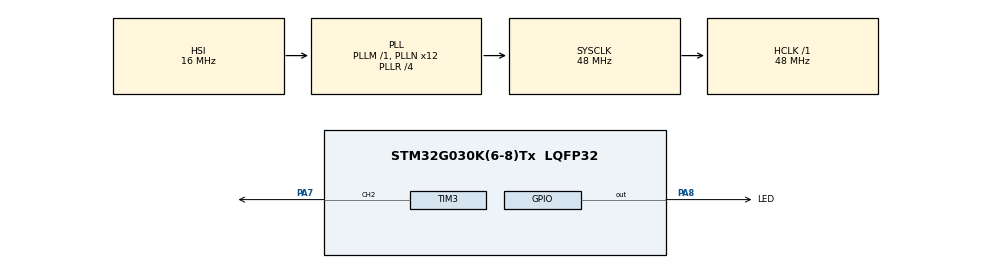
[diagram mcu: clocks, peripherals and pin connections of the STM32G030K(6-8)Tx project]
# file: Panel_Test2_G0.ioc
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Dma.Request0=TIM3_CH2
Dma.TIM3_CH2.0.Direction=DMA_MEMORY_TO_PERIPH
Dma.TIM3_CH2.0.EventEnable=DISABLE
Dma.TIM3_CH2.0.Instance=DMA1_Channel1
Dma.TIM3_CH2.0.MemDataAlignment=DMA_MDATAALIGN_BYTE
Dma.TIM3_CH2.0.MemInc=DMA_MINC_ENABLE
Dma.TIM3_CH2.0.Mode=DMA_CIRCULAR
Dma.TIM3_CH2.0.PeriphDataAlignment=DMA_PDATAALIGN_WORD
Dma.TIM3_CH2.0.PeriphInc=DMA_PINC_DISABLE
Dma.TIM3_CH2.0.Polarity=HAL_DMAMUX_REQ_GEN_RISING
Dma.TIM3_CH2.0.Priority=DMA_PRIORITY_VERY_HIGH
Dma.TIM3_CH2.0.RequestNumber=1
Dma.TIM3_CH2.0.SignalID=NONE
Dma.TIM3_CH2.0.SyncEnable=DISABLE
Dma.TIM3_CH2.0.SyncPolarity=HAL_DMAMUX_SYNC_NO_EVENT
Dma.TIM3_CH2.0.SyncRequestNumber=1
Dma.TIM3_CH2.0.SyncSignalID=NONE
Mcu.Family=STM32G0
Mcu.Name=STM32G030K(6-8)Tx
Mcu.Package=LQFP32
NVIC.DMA1_Channel1_IRQn=true\:0\:0\:false\:false\:true\:false\:true\:true
PA13.Mode=Serial_Wire
PA13.Signal=SYS_SWDIO
PA14-BOOT0.Mode=Serial_Wire
PA14-BOOT0.Signal=SYS_SWCLK
PA7.Signal=S_TIM3_CH2
PA8.GPIO_Label=LED
PA8.Signal=GPIO_Output
ProjectManager.HeapSize=0x200
ProjectManager.StackSize=0x400
ProjectManager.TargetToolchain=STM32CubeIDE
RCC.ADCFreq_Value=48000000
RCC.AHBFreq_Value=48000000
RCC.CortexFreq_Value=48000000
RCC.EXTERNAL_CLOCK_VALUE=12288000
RCC.HCLKFreq_Value=48000000
RCC.HSE_VALUE=8000000
RCC.HSI_VALUE=16000000
RCC.LSE_VALUE=32768
RCC.PLLN=12
RCC.PLLR=RCC_PLLR_DIV4
RCC.SYSCLKFreq_VALUE=48000000
RCC.SYSCLKSource=RCC_SYSCLKSOURCE_PLLCLK
RCC.VCOOutputFreq_Value=192000000
SH.S_TIM3_CH2.0=TIM3_CH2,PWM Generation2 CH2
TIM3.Channel-PWM\ Generation2\ CH2=TIM_CHANNEL_2
TIM3.OCFastMode_PWM-PWM\ Generation2\ CH2=TIM_OCFAST_ENABLE
TIM3.Period=15-1
TIM3.Prescaler=4-1
VP_TIM3_VS_ClockSourceINT.Mode=Internal
board=custom

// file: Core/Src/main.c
/* USER CODE BEGIN Header */
/**
  ******************************************************************************
  * @file           : main.c
  * @brief          : Main program body
  ******************************************************************************
  * @attention
  *
  * Copyright (c) 2024 STMicroelectronics.
  * All rights reserved.
  *
  * This software is licensed under terms that can be found in the LICENSE file
  * in the root directory of this software component.
  * If no LICENSE file comes with this software, it is provided AS-IS.
  *
  ******************************************************************************
  */
/* USER CODE END Header */
#include "main.h"

TIM_HandleTypeDef htim3;
DMA_HandleTypeDef hdma_tim3_ch2;

/* USER CODE BEGIN PV */

#define RST 50
#define LEDs 8
const uint16_t ELEMENT_NUM = 50+(LEDs*24);

uint8_t buffer[50+72] = {
		0,0,0,0,0,0,0,0,0,0,
		0,0,0,0,0,0,0,0,0,0,
		0,0,0,0,0,0,0,0,0,0,
		0,0,0,0,0,0,0,0,0,0,
		0,0,0,0,0,0,0,0,0,0,

		4,4,4,4,4,4,4,4,
		12,12,12,12,12,12,12,12,
		4,4,4,4,4,4,4,4,

		4,4,4,4,4,4,4,4,
		4,4,4,4,4,4,4,4,
		12,12,12,12,12,12,12,12,

		4,4,4,4,4,4,4,4,
		4,4,4,4,4,4,4,4,
		12,12,12,12,12,12,12,12,

};

uint8_t PWM_Buf[RST+(LEDs*24)];
uint8_t CLR_Buf[LEDs][3];

/* USER CODE END PV */

void SystemClock_Config(void);
static void MX_GPIO_Init(void);
static void MX_DMA_Init(void);
static void MX_TIM3_Init(void);

/* USER CODE BEGIN 0 */
void set_color(uint8_t buf[][3], uint16_t PIXEL_NUM, uint8_t red, uint8_t green, uint8_t blue){
	buf[PIXEL_NUM][0]=green;
	buf[PIXEL_NUM][1]=red;
	buf[PIXEL_NUM][2]=blue;
}
/* USER CODE END 0 */

int main(void)
{

  /* MCU Configuration--------------------------------------------------------*/

  /* Reset of all peripherals, Initializes the Flash interface and the Systick. */
  HAL_Init();

  /* Configure the system clock */
  SystemClock_Config();

  /* Initialize all configured peripherals */
  MX_GPIO_Init();
  MX_DMA_Init();
  MX_TIM3_Init();
  /* USER CODE BEGIN 2 */
  HAL_GPIO_WritePin(LED_GPIO_Port, LED_Pin, GPIO_PIN_SET);
//  HAL_TIM_PWM_Start_DMA( &htim3, TIM_CHANNEL_2, (uint32_t*)buffer, 50+72);

  for(int i=0; i<LEDs; i++){
    set_color(CLR_Buf, i, 3, 3, 0);
  }

  for(int i=0; i<RST; i++){
    PWM_Buf[i]=0;
  }

  for(int i=0; i<LEDs; i++){
	for(int j=0; j<3; j++){
      for(int k=7; k>=0; k--){
        int x=(CLR_Buf[i][j]>>k)&1;
        if(x==1){PWM_Buf[RST+(i*24)+(j*8)+(7-k)]=12;}
        else{PWM_Buf[RST+(i*24)+(j*8)+(7-k)]=4;}
      }
    }
  }

   HAL_TIM_PWM_Start_DMA( &htim3, TIM_CHANNEL_2, (uint32_t*)PWM_Buf, ELEMENT_NUM);

  /* USER CODE END 2 */

  /* Infinite loop */
  while (1)
  {

  }
}

void SystemClock_Config(void)
{
  RCC_OscInitTypeDef RCC_OscInitStruct = {0};
  RCC_ClkInitTypeDef RCC_ClkInitStruct = {0};

  /** Configure the main internal regulator output voltage
  */
  HAL_PWREx_ControlVoltageScaling(PWR_REGULATOR_VOLTAGE_SCALE1);

  /** Initializes the RCC Oscillators according to the specified parameters
  * in the RCC_OscInitTypeDef structure.
  */
  RCC_OscInitStruct.OscillatorType = RCC_OSCILLATORTYPE_HSI;
  RCC_OscInitStruct.HSIState = RCC_HSI_ON;
  RCC_OscInitStruct.HSIDiv = RCC_HSI_DIV1;
  RCC_OscInitStruct.HSICalibrationValue = RCC_HSICALIBRATION_DEFAULT;
  RCC_OscInitStruct.PLL.PLLState = RCC_PLL_ON;
  RCC_OscInitStruct.PLL.PLLSource = RCC_PLLSOURCE_HSI;
  RCC_OscInitStruct.PLL.PLLM = RCC_PLLM_DIV1;
  RCC_OscInitStruct.PLL.PLLN = 12;
  RCC_OscInitStruct.PLL.PLLP = RCC_PLLP_DIV2;
  RCC_OscInitStruct.PLL.PLLR = RCC_PLLR_DIV4;
  if (HAL_RCC_OscConfig(&RCC_OscInitStruct) != HAL_OK)
  {
    Error_Handler();
  }

  /** Initializes the CPU, AHB and APB buses clocks
  */
  RCC_ClkInitStruct.ClockType = RCC_CLOCKTYPE_HCLK|RCC_CLOCKTYPE_SYSCLK
                              |RCC_CLOCKTYPE_PCLK1;
  RCC_ClkInitStruct.SYSCLKSource = RCC_SYSCLKSOURCE_PLLCLK;
  RCC_ClkInitStruct.AHBCLKDivider = RCC_SYSCLK_DIV1;
  RCC_ClkInitStruct.APB1CLKDivider = RCC_HCLK_DIV1;

  if (HAL_RCC_ClockConfig(&RCC_ClkInitStruct, FLASH_LATENCY_1) != HAL_OK)
  {
    Error_Handler();
  }
}

static void MX_TIM3_Init(void)
{

  TIM_ClockConfigTypeDef sClockSourceConfig = {0};
  TIM_MasterConfigTypeDef sMasterConfig = {0};
  TIM_OC_InitTypeDef sConfigOC = {0};

  htim3.Instance = TIM3;
  htim3.Init.Prescaler = 4-1;
  htim3.Init.CounterMode = TIM_COUNTERMODE_UP;
  htim3.Init.Period = 15-1;
  htim3.Init.ClockDivision = TIM_CLOCKDIVISION_DIV1;
  htim3.Init.AutoReloadPreload = TIM_AUTORELOAD_PRELOAD_DISABLE;
  if (HAL_TIM_Base_Init(&htim3) != HAL_OK)
  {
    Error_Handler();
  }
  sClockSourceConfig.ClockSource = TIM_CLOCKSOURCE_INTERNAL;
  if (HAL_TIM_ConfigClockSource(&htim3, &sClockSourceConfig) != HAL_OK)
  {
    Error_Handler();
  }
  if (HAL_TIM_PWM_Init(&htim3) != HAL_OK)
  {
    Error_Handler();
  }
  sMasterConfig.MasterOutputTrigger = TIM_TRGO_RESET;
  sMasterConfig.MasterSlaveMode = TIM_MASTERSLAVEMODE_DISABLE;
  if (HAL_TIMEx_MasterConfigSynchronization(&htim3, &sMasterConfig) != HAL_OK)
  {
    Error_Handler();
  }
  sConfigOC.OCMode = TIM_OCMODE_PWM1;
  sConfigOC.Pulse = 0;
  sConfigOC.OCPolarity = TIM_OCPOLARITY_HIGH;
  sConfigOC.OCFastMode = TIM_OCFAST_ENABLE;
  if (HAL_TIM_PWM_ConfigChannel(&htim3, &sConfigOC, TIM_CHANNEL_2) != HAL_OK)
  {
    Error_Handler();
  }
  HAL_TIM_MspPostInit(&htim3);

}

static void MX_DMA_Init(void)
{

  /* DMA controller clock enable */
  __HAL_RCC_DMA1_CLK_ENABLE();

  /* DMA interrupt init */
  /* DMA1_Channel1_IRQn interrupt configuration */
  HAL_NVIC_SetPriority(DMA1_Channel1_IRQn, 0, 0);
  HAL_NVIC_EnableIRQ(DMA1_Channel1_IRQn);

}

static void MX_GPIO_Init(void)
{
  GPIO_InitTypeDef GPIO_InitStruct = {0};

  /* GPIO Ports Clock Enable */
  __HAL_RCC_GPIOA_CLK_ENABLE();

  /*Configure GPIO pin Output Level */
  HAL_GPIO_WritePin(LED_GPIO_Port, LED_Pin, GPIO_PIN_RESET);

  /*Configure GPIO pin : LED_Pin */
  GPIO_InitStruct.Pin = LED_Pin;
  GPIO_InitStruct.Mode = GPIO_MODE_OUTPUT_PP;
  GPIO_InitStruct.Pull = GPIO_NOPULL;
  GPIO_InitStruct.Speed = GPIO_SPEED_FREQ_LOW;
  HAL_GPIO_Init(LED_GPIO_Port, &GPIO_InitStruct);

}

void Error_Handler(void)
{
  __disable_irq();
  while (1)
  {
  }
}
